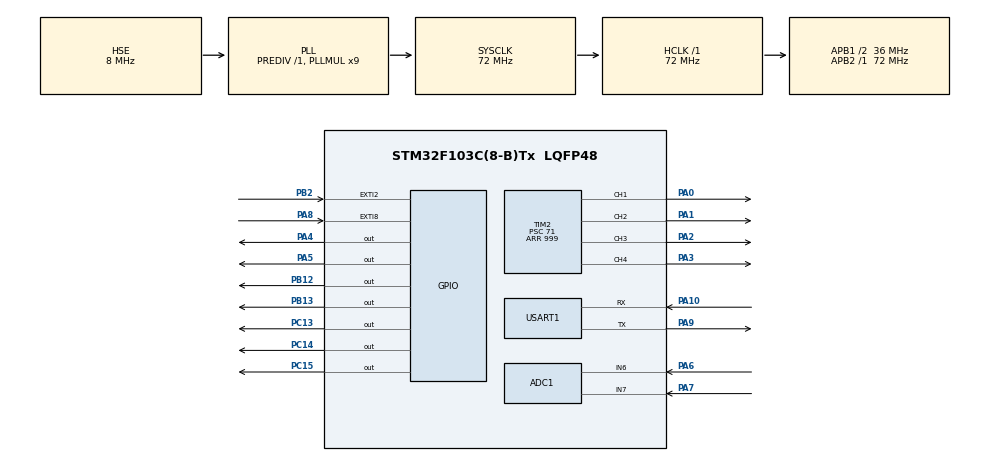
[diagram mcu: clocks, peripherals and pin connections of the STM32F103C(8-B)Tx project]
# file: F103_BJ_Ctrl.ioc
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ADC1.Channel-0\#ChannelRegularConversion=ADC_CHANNEL_6
ADC1.Channel-1\#ChannelRegularConversion=ADC_CHANNEL_7
ADC1.ContinuousConvMode=ENABLE
ADC1.NbrOfConversion=2
ADC1.NbrOfConversionFlag=1
ADC1.Rank-0\#ChannelRegularConversion=1
ADC1.Rank-1\#ChannelRegularConversion=2
ADC1.SamplingTime-0\#ChannelRegularConversion=ADC_SAMPLETIME_55CYCLES_5
ADC1.SamplingTime-1\#ChannelRegularConversion=ADC_SAMPLETIME_55CYCLES_5
ADC1.master=1
Dma.ADC1.2.Direction=DMA_PERIPH_TO_MEMORY
Dma.ADC1.2.Instance=DMA1_Channel1
Dma.ADC1.2.MemDataAlignment=DMA_MDATAALIGN_WORD
Dma.ADC1.2.MemInc=DMA_MINC_ENABLE
Dma.ADC1.2.Mode=DMA_CIRCULAR
Dma.ADC1.2.PeriphDataAlignment=DMA_PDATAALIGN_WORD
Dma.ADC1.2.PeriphInc=DMA_PINC_DISABLE
Dma.ADC1.2.Priority=DMA_PRIORITY_LOW
Dma.Request0=USART1_TX
Dma.Request1=USART1_RX
Dma.Request2=ADC1
Dma.USART1_RX.1.Direction=DMA_PERIPH_TO_MEMORY
Dma.USART1_RX.1.Instance=DMA1_Channel5
Dma.USART1_RX.1.MemDataAlignment=DMA_MDATAALIGN_BYTE
Dma.USART1_RX.1.MemInc=DMA_MINC_ENABLE
Dma.USART1_RX.1.Mode=DMA_NORMAL
Dma.USART1_RX.1.PeriphDataAlignment=DMA_PDATAALIGN_BYTE
Dma.USART1_RX.1.PeriphInc=DMA_PINC_DISABLE
Dma.USART1_RX.1.Priority=DMA_PRIORITY_LOW
Dma.USART1_TX.0.Direction=DMA_MEMORY_TO_PERIPH
Dma.USART1_TX.0.Instance=DMA1_Channel4
Dma.USART1_TX.0.MemDataAlignment=DMA_MDATAALIGN_BYTE
Dma.USART1_TX.0.MemInc=DMA_MINC_ENABLE
Dma.USART1_TX.0.Mode=DMA_NORMAL
Dma.USART1_TX.0.PeriphDataAlignment=DMA_PDATAALIGN_BYTE
Dma.USART1_TX.0.PeriphInc=DMA_PINC_DISABLE
Dma.USART1_TX.0.Priority=DMA_PRIORITY_LOW
Mcu.Family=STM32F1
Mcu.Name=STM32F103C(8-B)Tx
Mcu.Package=LQFP48
NVIC.ADC1_2_IRQn=true\:5\:0\:true\:false\:true\:true\:true
NVIC.DMA1_Channel1_IRQn=true\:5\:0\:true\:false\:true\:false\:true
NVIC.DMA1_Channel4_IRQn=true\:0\:0\:false\:false\:true\:false\:true
NVIC.DMA1_Channel5_IRQn=true\:0\:0\:false\:false\:true\:false\:true
NVIC.EXTI2_IRQn=true\:4\:0\:true\:false\:true\:true\:true
NVIC.EXTI9_5_IRQn=true\:4\:0\:true\:false\:true\:true\:true
NVIC.PriorityGroup=NVIC_PRIORITYGROUP_4
NVIC.TIM2_IRQn=true\:5\:0\:true\:false\:true\:true\:true
NVIC.USART1_IRQn=true\:6\:0\:true\:false\:true\:true\:true
PA0-WKUP.Signal=S_TIM2_CH1_ETR
PA1.Signal=S_TIM2_CH2
PA10.Mode=Asynchronous
PA10.Signal=USART1_RX
PA13.Mode=Serial_Wire
PA13.Signal=SYS_JTMS-SWDIO
PA14.Mode=Serial_Wire
PA14.Signal=SYS_JTCK-SWCLK
PA2.Signal=S_TIM2_CH3
PA3.Signal=S_TIM2_CH4
PA4.Signal=GPIO_Output
PA5.Signal=GPIO_Output
PA6.Signal=ADCx_IN6
PA7.Signal=ADCx_IN7
PA8.GPIO_ModeDefaultEXTI=GPIO_MODE_IT_FALLING
PA8.GPIO_PuPd=GPIO_PULLUP
PA8.Signal=GPXTI8
PA9.Mode=Asynchronous
PA9.Signal=USART1_TX
PB12.Signal=GPIO_Output
PB13.Signal=GPIO_Output
PB2.GPIO_ModeDefaultEXTI=GPIO_MODE_IT_FALLING
PB2.GPIO_PuPd=GPIO_PULLUP
PB2.Signal=GPXTI2
PC13-TAMPER-RTC.Signal=GPIO_Output
PC14-OSC32_IN.Signal=GPIO_Output
PC15-OSC32_OUT.Signal=GPIO_Output
PD0-OSC_IN.Mode=HSE-External-Oscillator
PD0-OSC_IN.Signal=RCC_OSC_IN
PD1-OSC_OUT.Mode=HSE-External-Oscillator
PD1-OSC_OUT.Signal=RCC_OSC_OUT
ProjectManager.HeapSize=0x200
ProjectManager.StackSize=0x400
ProjectManager.TargetToolchain=MDK-ARM V5.27
RCC.ADCPresc=RCC_ADCPCLK2_DIV6
RCC.AHBFreq_Value=72000000
RCC.APB1CLKDivider=RCC_HCLK_DIV2
RCC.APB1Freq_Value=36000000
RCC.APB1TimFreq_Value=72000000
RCC.APB2Freq_Value=72000000
RCC.APB2TimFreq_Value=72000000
RCC.HCLKFreq_Value=72000000
RCC.PLLMUL=RCC_PLL_MUL9
RCC.PLLSourceVirtual=RCC_PLLSOURCE_HSE
RCC.SYSCLKFreq_VALUE=72000000
RCC.SYSCLKSource=RCC_SYSCLKSOURCE_PLLCLK
RCC.USBFreq_Value=72000000
SH.ADCx_IN6.0=ADC1_IN6,IN6
SH.ADCx_IN7.0=ADC1_IN7,IN7
SH.S_TIM2_CH1_ETR.0=TIM2_CH1,PWM Generation1 CH1
SH.S_TIM2_CH2.0=TIM2_CH2,PWM Generation2 CH2
SH.S_TIM2_CH3.0=TIM2_CH3,PWM Generation3 CH3
SH.S_TIM2_CH4.0=TIM2_CH4,PWM Generation4 CH4
TIM2.Channel-PWM\ Generation1\ CH1=TIM_CHANNEL_1
TIM2.Channel-PWM\ Generation2\ CH2=TIM_CHANNEL_2
TIM2.Channel-PWM\ Generation3\ CH3=TIM_CHANNEL_3
TIM2.Channel-PWM\ Generation4\ CH4=TIM_CHANNEL_4
TIM2.Period=999
TIM2.Prescaler=71
TIM2.Pulse-PWM\ Generation1\ CH1=500
TIM2.Pulse-PWM\ Generation2\ CH2=500
TIM2.Pulse-PWM\ Generation3\ CH3=500
TIM2.Pulse-PWM\ Generation4\ CH4=500
USART1.VirtualMode=VM_ASYNC
board=custom

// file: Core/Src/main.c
/* USER CODE BEGIN Header */
/**
 ******************************************************************************
 * @file           : main.c
 * @brief          : Main program body
 ******************************************************************************
 * @attention
 *
 * <h2><center>&copy; Copyright (c) 2023 STMicroelectronics.
 * All rights reserved.</center></h2>
 *
 * This software component is licensed by ST under BSD 3-Clause license,
 * the "License"; You may not use this file except in compliance with the
 * License. You may obtain a copy of the License at:
 *                        opensource.org/licenses/BSD-3-Clause
 *
 ******************************************************************************
 */
/* USER CODE END Header */
#include "main.h"
#include "adc.h"
#include "dma.h"
#include "tim.h"
#include "usart.h"
#include "gpio.h"

/* USER CODE BEGIN Includes */
#include "callback.h"
#include "BJ_Ctrl.h"
/* USER CODE END Includes */

void SystemClock_Config(void);
/* USER CODE BEGIN PFP */
uint32_t ADC_Value[100];
/* USER CODE END PFP */

int main(void)
{

  /* MCU Configuration--------------------------------------------------------*/

  /* Reset of all peripherals, Initializes the Flash interface and the Systick. */
  HAL_Init();

  /* Configure the system clock */
  SystemClock_Config();

  /* Initialize all configured peripherals */
  MX_GPIO_Init();
  MX_DMA_Init();
  MX_TIM2_Init();
  MX_USART1_UART_Init();
  MX_ADC1_Init();
  /* USER CODE BEGIN 2 */
  TIM2->PSC=750;
  HAL_TIM_PWM_Start_IT(&htim2, TIM_CHANNEL_1);

  /* USER CODE END 2 */

  /* Infinite loop */
  /* USER CODE BEGIN WHILE */
  while (1)
  {

    BJ_do_step(533, 1);
    HAL_Delay(1);
    while(TIM2->CCR1!=0);

    HAL_Delay(4000);

    /* USER CODE END WHILE */

  }
}

void SystemClock_Config(void)
{
  RCC_OscInitTypeDef RCC_OscInitStruct = {0};
  RCC_ClkInitTypeDef RCC_ClkInitStruct = {0};
  RCC_PeriphCLKInitTypeDef PeriphClkInit = {0};

  /** Initializes the RCC Oscillators according to the specified parameters
   * in the RCC_OscInitTypeDef structure.
   */
  RCC_OscInitStruct.OscillatorType = RCC_OSCILLATORTYPE_HSE;
  RCC_OscInitStruct.HSEState = RCC_HSE_ON;
  RCC_OscInitStruct.HSEPredivValue = RCC_HSE_PREDIV_DIV1;
  RCC_OscInitStruct.HSIState = RCC_HSI_ON;
  RCC_OscInitStruct.PLL.PLLState = RCC_PLL_ON;
  RCC_OscInitStruct.PLL.PLLSource = RCC_PLLSOURCE_HSE;
  RCC_OscInitStruct.PLL.PLLMUL = RCC_PLL_MUL9;
  if (HAL_RCC_OscConfig(&RCC_OscInitStruct) != HAL_OK)
  {
    Error_Handler();
  }
  /** Initializes the CPU, AHB and APB buses clocks
   */
  RCC_ClkInitStruct.ClockType = RCC_CLOCKTYPE_HCLK | RCC_CLOCKTYPE_SYSCLK | RCC_CLOCKTYPE_PCLK1 | RCC_CLOCKTYPE_PCLK2;
  RCC_ClkInitStruct.SYSCLKSource = RCC_SYSCLKSOURCE_PLLCLK;
  RCC_ClkInitStruct.AHBCLKDivider = RCC_SYSCLK_DIV1;
  RCC_ClkInitStruct.APB1CLKDivider = RCC_HCLK_DIV2;
  RCC_ClkInitStruct.APB2CLKDivider = RCC_HCLK_DIV1;

  if (HAL_RCC_ClockConfig(&RCC_ClkInitStruct, FLASH_LATENCY_2) != HAL_OK)
  {
    Error_Handler();
  }
  PeriphClkInit.PeriphClockSelection = RCC_PERIPHCLK_ADC;
  PeriphClkInit.AdcClockSelection = RCC_ADCPCLK2_DIV6;
  if (HAL_RCCEx_PeriphCLKConfig(&PeriphClkInit) != HAL_OK)
  {
    Error_Handler();
  }
}

void Error_Handler(void)
{
  __disable_irq();
  while (1)
  {
  }
}

/************************ (C) COPYRIGHT STMicroelectronics *****END OF FILE****/
